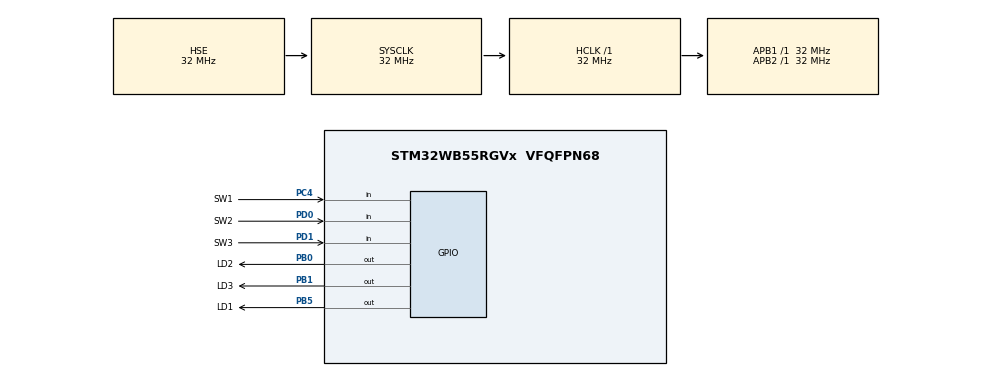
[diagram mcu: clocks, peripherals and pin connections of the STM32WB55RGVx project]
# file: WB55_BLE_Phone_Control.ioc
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ADC1.Channel-1\#ChannelRegularConversion=ADC_CHANNEL_VREFINT
ADC1.Channel-2\#ChannelRegularConversion=ADC_CHANNEL_TEMPSENSOR
ADC1.NbrOfConversion=2
ADC1.NbrOfConversionFlag=1
ADC1.OffsetNumber-1\#ChannelRegularConversion=ADC_OFFSET_NONE
ADC1.OffsetNumber-2\#ChannelRegularConversion=ADC_OFFSET_NONE
ADC1.Rank-1\#ChannelRegularConversion=1
ADC1.Rank-2\#ChannelRegularConversion=2
ADC1.SamplingTime-1\#ChannelRegularConversion=ADC_SAMPLETIME_640CYCLES_5
ADC1.SamplingTime-2\#ChannelRegularConversion=ADC_SAMPLETIME_640CYCLES_5
ADC1.master=1
IWDG.Prescaler=IWDG_PRESCALER_64
Mcu.Family=STM32WB
Mcu.Name=STM32WB55RGVx
Mcu.Package=VFQFPN68
NVIC.HSEM_IRQn=true\:0\:0\:false\:false\:true\:false\:true\:true
NVIC.IPCC_C1_RX_IRQn=true\:0\:0\:false\:false\:true\:true\:true\:true
NVIC.IPCC_C1_TX_IRQn=true\:0\:0\:false\:false\:true\:true\:true\:true
NVIC.PriorityGroup=NVIC_PRIORITYGROUP_4
NVIC.RTC_WKUP_IRQn=true\:0\:0\:false\:false\:true\:true\:true\:true
OSC_IN.Mode=HSE-External-Oscillator
OSC_IN.Signal=RCC_OSC_IN
OSC_OUT.Mode=HSE-External-Oscillator
OSC_OUT.Signal=RCC_OSC_OUT
PB0.GPIO_Label=LD2
PB0.Signal=GPIO_Output
PB1.GPIO_Label=LD3
PB1.Signal=GPIO_Output
PB5.GPIO_Label=LD1
PB5.Signal=GPIO_Output
PC14-OSC32_IN.Mode=LSE-External-Oscillator
PC14-OSC32_IN.Signal=RCC_OSC32_IN
PC15-OSC32_OUT.Mode=LSE-External-Oscillator
PC15-OSC32_OUT.Signal=RCC_OSC32_OUT
PC4.GPIO_Label=SW1
PC4.GPIO_PuPd=GPIO_PULLUP
PC4.Signal=GPIO_Input
PD0.GPIO_Label=SW2
PD0.GPIO_PuPd=GPIO_PULLUP
PD0.Signal=GPIO_Input
PD1.GPIO_Label=SW3
PD1.GPIO_PuPd=GPIO_PULLUP
PD1.Signal=GPIO_Input
ProjectManager.HeapSize=0x200
ProjectManager.StackSize=0x400
ProjectManager.TargetToolchain=STM32CubeIDE
RCC.ADCFreq_Value=128000000
RCC.AHBFreq_Value=32000000
RCC.APB1Freq_Value=32000000
RCC.APB1TimFreq_Value=32000000
RCC.APB2Freq_Value=32000000
RCC.APB2TimFreq_Value=32000000
RCC.APB3Freq_Value=16000000
RCC.CortexFreq_Value=32000000
RCC.HCLKFreq_Value=32000000
RCC.HSE_VALUE=32000000
RCC.HSI48_VALUE=48000000
RCC.HSI_VALUE=16000000
RCC.MSIClockRange=RCC_MSIRANGE_10
RCC.RFWKPClockSelection=RCC_RFWKPCLKSOURCE_LSE
RCC.RTCClockSelection=RCC_RTCCLKSOURCE_LSE
RCC.SMPSCLockSelection=RCC_SMPSCLKSOURCE_HSE
RCC.SMPSDivider=4
RCC.SYSCLKFreq_VALUE=32000000
RCC.SYSCLKSource=RCC_SYSCLKSOURCE_HSE
RCC.USBFreq_Value=128000000
RCC.VCOOutputFreq_Value=256000000
RF1.Mode=RF1_Activate
RF1.Signal=RF_RF1
STM32_WPAN.AD_TYPE_COMPLETE_LOCAL_NAME=WB55_CTRL
STM32_WPAN.AD_TYPE_COMPLETE_LOCAL_NAME_LENGTH=10
STM32_WPAN.BLE_CFG_DIS_FIRMWARE_REVISION_STRING=1
STM32_WPAN.BLE_CFG_DIS_HARDWARE_REVISION_STRING=1
STM32_WPAN.BLE_CFG_DIS_MODEL_NUMBER_STRING=1
STM32_WPAN.BT_SIG_HEALTH_THERMOMETER_SENSOR=Enabled
STM32_WPAN.CFG_GAP_DEVICE_NAME=WB55_CTRL
STM32_WPAN.CFG_GAP_DEVICE_NAME_LENGTH=9
STM32_WPAN.CFG_LSCLK_LSE=0
STM32_WPAN.CUSTOM_P2P_SERVER=Disabled
STM32_WPAN.CUSTOM_TEMPLATE=Enabled
STM32_WPAN.INCLUDE_AD_TYPE_COMPLETE_LOCAL_NAME=1
STM32_WPAN.INCLUDE_AD_TYPE_TX_POWER_LEVEL=1
STM32_WPAN.NUMBER_OF_SERVICES=2
STM32_WPAN.SERVICE1_CHAR1_GATT_NOTIFY_READ_REQ_AND_WAIT_FOR_APPL_RESP=\ 
STM32_WPAN.SERVICE1_CHAR1_GATT_NOTIFY_WRITE_REQ_AND_WAIT_FOR_APPL_RESP=\ 
STM32_WPAN.SERVICE1_CHAR1_LENGTH_CHARACTERISTIC=CHAR_VALUE_LEN_VARIABLE
STM32_WPAN.SERVICE1_CHAR1_LONG_NAME=My_LED_Char
STM32_WPAN.SERVICE1_CHAR1_PROP_READ=CHAR_PROP_READ
STM32_WPAN.SERVICE1_CHAR1_PROP_WRITE=CHAR_PROP_WRITE
STM32_WPAN.SERVICE1_CHAR1_PROP_WRITE_WITHOUT_RESP=CHAR_PROP_WRITE_WITHOUT_RESP
STM32_WPAN.SERVICE1_CHAR1_SHORT_NAME=LED_C
STM32_WPAN.SERVICE1_CHAR1_UUID=FE 41
STM32_WPAN.SERVICE1_CHAR1_VALUE_LENGTH=2
STM32_WPAN.SERVICE1_CHAR2_GATT_NOTIFY_READ_REQ_AND_WAIT_FOR_APPL_RESP=\ 
STM32_WPAN.SERVICE1_CHAR2_GATT_NOTIFY_WRITE_REQ_AND_WAIT_FOR_APPL_RESP=\ 
STM32_WPAN.SERVICE1_CHAR2_LENGTH_CHARACTERISTIC=CHAR_VALUE_LEN_VARIABLE
STM32_WPAN.SERVICE1_CHAR2_LONG_NAME=My_Switch_Char
STM32_WPAN.SERVICE1_CHAR2_PROP_NOTIFY=CHAR_PROP_NOTIFY
STM32_WPAN.SERVICE1_CHAR2_SHORT_NAME=SWITCH_C
STM32_WPAN.SERVICE1_CHAR2_UUID=FE 42
STM32_WPAN.SERVICE1_CHAR2_VALUE_LENGTH=2
STM32_WPAN.SERVICE1_CHAR3_LENGTH_CHARACTERISTIC=CHAR_VALUE_LEN_CONSTANT
STM32_WPAN.SERVICE1_CHAR3_LONG_NAME=VDDA
STM32_WPAN.SERVICE1_CHAR3_PROP_READ=CHAR_PROP_READ
STM32_WPAN.SERVICE1_CHAR3_SHORT_NAME=VDDA_C
STM32_WPAN.SERVICE1_CHAR3_UUID=FE 43
STM32_WPAN.SERVICE1_CHAR3_VALUE_LENGTH=2
STM32_WPAN.SERVICE1_CHAR4_LONG_NAME=Uptime
STM32_WPAN.SERVICE1_CHAR4_PROP_READ=CHAR_PROP_READ
STM32_WPAN.SERVICE1_CHAR4_SHORT_NAME=UPTIME_C
STM32_WPAN.SERVICE1_CHAR4_UUID=FE 44
STM32_WPAN.SERVICE1_CHAR4_VALUE_LENGTH=4
STM32_WPAN.SERVICE1_CHAR5_LONG_NAME=Reset_Reason
STM32_WPAN.SERVICE1_CHAR5_PROP_READ=CHAR_PROP_READ
STM32_WPAN.SERVICE1_CHAR5_SHORT_NAME=RESET_C
STM32_WPAN.SERVICE1_CHAR5_UUID=FE 45
STM32_WPAN.SERVICE1_CHAR5_VALUE_LENGTH=2
STM32_WPAN.SERVICE1_LONG_NAME=My_P2P_Server
STM32_WPAN.SERVICE1_NUMBER_OF_CHARACTERISTICS=5
STM32_WPAN.SERVICE1_SHORT_NAME=My_P2P
STM32_WPAN.SERVICE1_UUID=FE 40
STM32_WPAN.SERVICE2_CHAR1_GATT_NOTIFY_ATTRIBUTE_WRITE=\ 
STM32_WPAN.SERVICE2_CHAR1_GATT_NOTIFY_WRITE_REQ_AND_WAIT_FOR_APPL_RESP=\ 
STM32_WPAN.SERVICE2_CHAR1_LONG_NAME=BLE_Connection_Stats
STM32_WPAN.SERVICE2_CHAR1_PROP_READ=CHAR_PROP_READ
STM32_WPAN.SERVICE2_CHAR1_SHORT_NAME=CONN_STATS
STM32_WPAN.SERVICE2_CHAR1_UUID=FE 46
STM32_WPAN.SERVICE2_CHAR1_VALUE_LENGTH=5
STM32_WPAN.SERVICE2_CHAR2_GATT_NOTIFY_ATTRIBUTE_WRITE=\ 
STM32_WPAN.SERVICE2_CHAR2_GATT_NOTIFY_WRITE_REQ_AND_WAIT_FOR_APPL_RESP=\ 
STM32_WPAN.SERVICE2_CHAR2_LONG_NAME=Button_Press_Counters
STM32_WPAN.SERVICE2_CHAR2_PROP_READ=CHAR_PROP_READ
STM32_WPAN.SERVICE2_CHAR2_SHORT_NAME=BUTTON_CNT
STM32_WPAN.SERVICE2_CHAR2_UUID=FE 47
STM32_WPAN.SERVICE2_CHAR2_VALUE_LENGTH=6
STM32_WPAN.SERVICE2_CHAR3_GATT_NOTIFY_READ_REQ_AND_WAIT_FOR_APPL_RESP=\ 
STM32_WPAN.SERVICE2_CHAR3_GATT_NOTIFY_WRITE_REQ_AND_WAIT_FOR_APPL_RESP=\ 
STM32_WPAN.SERVICE2_CHAR3_LONG_NAME=Software_Reset
STM32_WPAN.SERVICE2_CHAR3_PROP_WRITE=CHAR_PROP_WRITE
STM32_WPAN.SERVICE2_CHAR3_SHORT_NAME=SW_RESET
STM32_WPAN.SERVICE2_CHAR3_UUID=FE 48
STM32_WPAN.SERVICE2_CHAR3_VALUE_LENGTH=2
STM32_WPAN.SERVICE2_CHAR4_GATT_NOTIFY_ATTRIBUTE_WRITE=\ 
STM32_WPAN.SERVICE2_CHAR4_GATT_NOTIFY_WRITE_REQ_AND_WAIT_FOR_APPL_RESP=\ 
STM32_WPAN.SERVICE2_CHAR4_LONG_NAME=Connection_Duration
STM32_WPAN.SERVICE2_CHAR4_PROP_READ=CHAR_PROP_READ
STM32_WPAN.SERVICE2_CHAR4_SHORT_NAME=CONN_TIME
STM32_WPAN.SERVICE2_CHAR4_UUID=FE 49
STM32_WPAN.SERVICE2_CHAR4_VALUE_LENGTH=4
STM32_WPAN.SERVICE2_CHAR5_GATT_NOTIFY_READ_REQ_AND_WAIT_FOR_APPL_RESP=\ 
STM32_WPAN.SERVICE2_CHAR5_GATT_NOTIFY_WRITE_REQ_AND_WAIT_FOR_APPL_RESP=\ 
STM32_WPAN.SERVICE2_CHAR5_LONG_NAME=Clear_Diagnostics
STM32_WPAN.SERVICE2_CHAR5_PROP_WRITE=CHAR_PROP_WRITE
STM32_WPAN.SERVICE2_CHAR5_SHORT_NAME=CLEAR_DIAG
STM32_WPAN.SERVICE2_CHAR5_UUID=FE 4A
STM32_WPAN.SERVICE2_CHAR5_VALUE_LENGTH=2
STM32_WPAN.SERVICE2_LONG_NAME=Diagnostics_Service
STM32_WPAN.SERVICE2_NUMBER_OF_CHARACTERISTICS=5
STM32_WPAN.SERVICE2_SHORT_NAME=DIAG
STM32_WPAN.SERVICE2_UUID=FE 50
VP_ADC1_TempSens_Input.Mode=IN-TempSens
VP_ADC1_Vref_Input.Mode=IN-Vrefint
VP_HSEM_VS_HSEM.Mode=HSEM_Activate
VP_IPCC_VS_IPCC.Mode=IPCC_Activate
VP_IWDG_VS_IWDG.Mode=IWDG_Activate
VP_MEMORYMAP_VS_MEMORYMAP.Mode=CurAppReg
VP_RTC_VS_RTC_Activate.Mode=RTC_Enabled
VP_RTC_VS_RTC_WakeUp_intern.Mode=WakeUp
VP_SEQUENCER_VS_SEQUENCER.Mode=SEQUENCER_Enabled
VP_STM32_WPAN_VS_BLE_HOST.Mode=STM32_WPAN_Enabled
VP_TINY_LPM_VS_TINY_LPM.Mode=TINY_LPM_Enabled
board=custom

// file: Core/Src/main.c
/* USER CODE BEGIN Header */
/**
  ******************************************************************************
  * @file           : main.c
  * @brief          : Main program body
  ******************************************************************************
  * @attention
  *
  * Copyright (c) 2026 STMicroelectronics.
  * All rights reserved.
  *
  * This software is licensed under terms that can be found in the LICENSE file
  * in the root directory of this software component.
  * If no LICENSE file comes with this software, it is provided AS-IS.
  *
  ******************************************************************************
  */
/* USER CODE END Header */
#include "main.h"

/* USER CODE BEGIN Includes */

#include "custom_app.h"

/* USER CODE END Includes */

ADC_HandleTypeDef hadc1;

IPCC_HandleTypeDef hipcc;

IWDG_HandleTypeDef hiwdg;

RTC_HandleTypeDef hrtc;

void SystemClock_Config(void);
void PeriphCommonClock_Config(void);
static void MX_GPIO_Init(void);
static void MX_ADC1_Init(void);
static void MX_IPCC_Init(void);
static void MX_RTC_Init(void);
static void MX_IWDG_Init(void);
static void MX_RF_Init(void);

int main(void)
{

  /* MCU Configuration--------------------------------------------------------*/

  /* Reset of all peripherals, Initializes the Flash interface and the Systick. */
  HAL_Init();
  /* Config code for STM32_WPAN (HSE Tuning must be done before system clock configuration) */
  MX_APPE_Config();

  /* Configure the system clock */
  SystemClock_Config();

  /* Configure the peripherals common clocks */
  PeriphCommonClock_Config();

  /* IPCC initialisation */
  MX_IPCC_Init();

  /* Initialize all configured peripherals */
  MX_GPIO_Init();
  MX_ADC1_Init();
  MX_RTC_Init();
  MX_IWDG_Init();
  MX_RF_Init();

  /* Init code for STM32_WPAN */
  MX_APPE_Init();

  /* Infinite loop */
  /* USER CODE BEGIN WHILE */

  (void)HAL_IWDG_Refresh(&hiwdg);

  while (1)
  {
    /* USER CODE END WHILE */
    MX_APPE_Process();

    /* USER CODE BEGIN 3 */

    Custom_APP_Process();

    (void)HAL_IWDG_Refresh(&hiwdg);
  }
  /* USER CODE END 3 */
}

void SystemClock_Config(void)
{
  RCC_OscInitTypeDef RCC_OscInitStruct = {0};
  RCC_ClkInitTypeDef RCC_ClkInitStruct = {0};

  /** Macro to configure the PLL multiplication factor
  */
  __HAL_RCC_PLL_PLLM_CONFIG(RCC_PLLM_DIV1);

  /** Macro to configure the PLL clock source
  */
  __HAL_RCC_PLL_PLLSOURCE_CONFIG(RCC_PLLSOURCE_MSI);

  /** Configure LSE Drive Capability
  */
  HAL_PWR_EnableBkUpAccess();
  __HAL_RCC_LSEDRIVE_CONFIG(RCC_LSEDRIVE_MEDIUMHIGH);

  /** Configure the main internal regulator output voltage
  */
  __HAL_PWR_VOLTAGESCALING_CONFIG(PWR_REGULATOR_VOLTAGE_SCALE1);

  /** Initializes the RCC Oscillators according to the specified parameters
  * in the RCC_OscInitTypeDef structure.
  */
  RCC_OscInitStruct.OscillatorType = RCC_OSCILLATORTYPE_HSI|RCC_OSCILLATORTYPE_LSI1
                              |RCC_OSCILLATORTYPE_HSE|RCC_OSCILLATORTYPE_LSE
                              |RCC_OSCILLATORTYPE_MSI;
  RCC_OscInitStruct.HSEState = RCC_HSE_ON;
  RCC_OscInitStruct.LSEState = RCC_LSE_ON;
  RCC_OscInitStruct.HSIState = RCC_HSI_ON;
  RCC_OscInitStruct.MSIState = RCC_MSI_ON;
  RCC_OscInitStruct.HSICalibrationValue = RCC_HSICALIBRATION_DEFAULT;
  RCC_OscInitStruct.MSICalibrationValue = RCC_MSICALIBRATION_DEFAULT;
  RCC_OscInitStruct.MSIClockRange = RCC_MSIRANGE_10;
  RCC_OscInitStruct.LSIState = RCC_LSI_ON;
  RCC_OscInitStruct.PLL.PLLState = RCC_PLL_NONE;
  if (HAL_RCC_OscConfig(&RCC_OscInitStruct) != HAL_OK)
  {
    Error_Handler();
  }

  /** Configure the SYSCLKSource, HCLK, PCLK1 and PCLK2 clocks dividers
  */
  RCC_ClkInitStruct.ClockType = RCC_CLOCKTYPE_HCLK4|RCC_CLOCKTYPE_HCLK2
                              |RCC_CLOCKTYPE_HCLK|RCC_CLOCKTYPE_SYSCLK
                              |RCC_CLOCKTYPE_PCLK1|RCC_CLOCKTYPE_PCLK2;
  RCC_ClkInitStruct.SYSCLKSource = RCC_SYSCLKSOURCE_HSE;
  RCC_ClkInitStruct.AHBCLKDivider = RCC_SYSCLK_DIV1;
  RCC_ClkInitStruct.APB1CLKDivider = RCC_HCLK_DIV1;
  RCC_ClkInitStruct.APB2CLKDivider = RCC_HCLK_DIV1;
  RCC_ClkInitStruct.AHBCLK2Divider = RCC_SYSCLK_DIV1;
  RCC_ClkInitStruct.AHBCLK4Divider = RCC_SYSCLK_DIV1;

  if (HAL_RCC_ClockConfig(&RCC_ClkInitStruct, FLASH_LATENCY_1) != HAL_OK)
  {
    Error_Handler();
  }
}

void PeriphCommonClock_Config(void)
{
  RCC_PeriphCLKInitTypeDef PeriphClkInitStruct = {0};

  /** Initializes the peripherals clock
  */
  PeriphClkInitStruct.PeriphClockSelection = RCC_PERIPHCLK_SMPS|RCC_PERIPHCLK_RFWAKEUP;
  PeriphClkInitStruct.RFWakeUpClockSelection = RCC_RFWKPCLKSOURCE_LSE;
  PeriphClkInitStruct.SmpsClockSelection = RCC_SMPSCLKSOURCE_HSE;
  PeriphClkInitStruct.SmpsDivSelection = RCC_SMPSCLKDIV_RANGE1;

  if (HAL_RCCEx_PeriphCLKConfig(&PeriphClkInitStruct) != HAL_OK)
  {
    Error_Handler();
  }
}

static void MX_ADC1_Init(void)
{

  ADC_ChannelConfTypeDef sConfig = {0};

  /** Common config
  */
  hadc1.Instance = ADC1;
  hadc1.Init.ClockPrescaler = ADC_CLOCK_ASYNC_DIV2;
  hadc1.Init.Resolution = ADC_RESOLUTION_12B;
  hadc1.Init.DataAlign = ADC_DATAALIGN_RIGHT;
  hadc1.Init.ScanConvMode = ADC_SCAN_ENABLE;
  hadc1.Init.EOCSelection = ADC_EOC_SINGLE_CONV;
  hadc1.Init.LowPowerAutoWait = DISABLE;
  hadc1.Init.ContinuousConvMode = DISABLE;
  hadc1.Init.NbrOfConversion = 2;
  hadc1.Init.DiscontinuousConvMode = DISABLE;
  hadc1.Init.ExternalTrigConv = ADC_SOFTWARE_START;
  hadc1.Init.ExternalTrigConvEdge = ADC_EXTERNALTRIGCONVEDGE_NONE;
  hadc1.Init.DMAContinuousRequests = DISABLE;
  hadc1.Init.Overrun = ADC_OVR_DATA_PRESERVED;
  hadc1.Init.OversamplingMode = DISABLE;
  if (HAL_ADC_Init(&hadc1) != HAL_OK)
  {
    Error_Handler();
  }

  /** Configure Regular Channel
  */
  sConfig.Channel = ADC_CHANNEL_VREFINT;
  sConfig.Rank = ADC_REGULAR_RANK_1;
  sConfig.SamplingTime = ADC_SAMPLETIME_640CYCLES_5;
  sConfig.SingleDiff = ADC_SINGLE_ENDED;
  sConfig.OffsetNumber = ADC_OFFSET_NONE;
  sConfig.Offset = 0;
  if (HAL_ADC_ConfigChannel(&hadc1, &sConfig) != HAL_OK)
  {
    Error_Handler();
  }

  /** Configure Regular Channel
  */
  sConfig.Channel = ADC_CHANNEL_TEMPSENSOR;
  sConfig.Rank = ADC_REGULAR_RANK_2;
  if (HAL_ADC_ConfigChannel(&hadc1, &sConfig) != HAL_OK)
  {
    Error_Handler();
  }

}

static void MX_IPCC_Init(void)
{

  hipcc.Instance = IPCC;
  if (HAL_IPCC_Init(&hipcc) != HAL_OK)
  {
    Error_Handler();
  }

}

static void MX_IWDG_Init(void)
{

  hiwdg.Instance = IWDG;
  hiwdg.Init.Prescaler = IWDG_PRESCALER_64;
  hiwdg.Init.Window = 4095;
  hiwdg.Init.Reload = 4095;
  if (HAL_IWDG_Init(&hiwdg) != HAL_OK)
  {
    Error_Handler();
  }

}

static void MX_RF_Init(void)
{

}

static void MX_RTC_Init(void)
{

  /** Initialize RTC Only
  */
  hrtc.Instance = RTC;
  hrtc.Init.HourFormat = RTC_HOURFORMAT_24;
  hrtc.Init.AsynchPrediv = CFG_RTC_ASYNCH_PRESCALER;
  hrtc.Init.SynchPrediv = CFG_RTC_SYNCH_PRESCALER;
  hrtc.Init.OutPut = RTC_OUTPUT_DISABLE;
  hrtc.Init.OutPutPolarity = RTC_OUTPUT_POLARITY_HIGH;
  hrtc.Init.OutPutType = RTC_OUTPUT_TYPE_OPENDRAIN;
  hrtc.Init.OutPutRemap = RTC_OUTPUT_REMAP_NONE;
  if (HAL_RTC_Init(&hrtc) != HAL_OK)
  {
    Error_Handler();
  }

  /** Enable the WakeUp
  */
  if (HAL_RTCEx_SetWakeUpTimer_IT(&hrtc, 0, RTC_WAKEUPCLOCK_RTCCLK_DIV16) != HAL_OK)
  {
    Error_Handler();
  }

}

static void MX_GPIO_Init(void)
{
  GPIO_InitTypeDef GPIO_InitStruct = {0};

  /* GPIO Ports Clock Enable */
  __HAL_RCC_GPIOC_CLK_ENABLE();
  __HAL_RCC_GPIOB_CLK_ENABLE();
  __HAL_RCC_GPIOD_CLK_ENABLE();

  /*Configure GPIO pin Output Level */
  HAL_GPIO_WritePin(GPIOB, LD2_Pin|LD3_Pin|LD1_Pin, GPIO_PIN_RESET);

  /*Configure GPIO pin : SW1_Pin */
  GPIO_InitStruct.Pin = SW1_Pin;
  GPIO_InitStruct.Mode = GPIO_MODE_INPUT;
  GPIO_InitStruct.Pull = GPIO_PULLUP;
  HAL_GPIO_Init(SW1_GPIO_Port, &GPIO_InitStruct);

  /*Configure GPIO pins : LD2_Pin LD3_Pin LD1_Pin */
  GPIO_InitStruct.Pin = LD2_Pin|LD3_Pin|LD1_Pin;
  GPIO_InitStruct.Mode = GPIO_MODE_OUTPUT_PP;
  GPIO_InitStruct.Pull = GPIO_NOPULL;
  GPIO_InitStruct.Speed = GPIO_SPEED_FREQ_LOW;
  HAL_GPIO_Init(GPIOB, &GPIO_InitStruct);

  /*Configure GPIO pins : SW2_Pin SW3_Pin */
  GPIO_InitStruct.Pin = SW2_Pin|SW3_Pin;
  GPIO_InitStruct.Mode = GPIO_MODE_INPUT;
  GPIO_InitStruct.Pull = GPIO_PULLUP;
  HAL_GPIO_Init(GPIOD, &GPIO_InitStruct);

}

void Error_Handler(void)
{
  __disable_irq();
  while (1)
  {
  }
}
